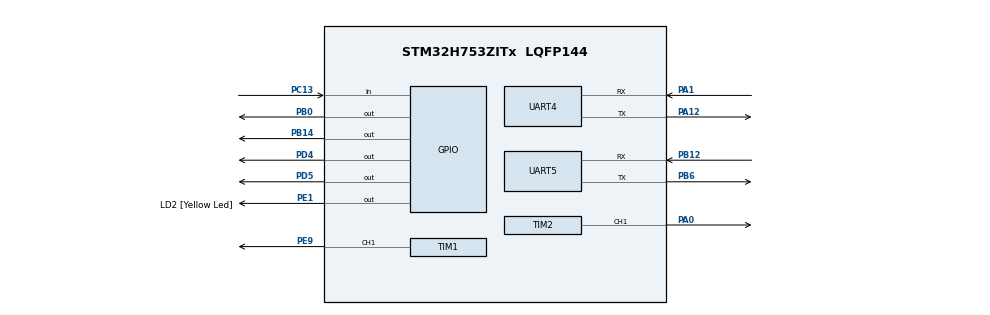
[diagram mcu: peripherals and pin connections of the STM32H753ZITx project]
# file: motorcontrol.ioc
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CORTEX_M7.CPU_DCache=Disabled
CORTEX_M7.CPU_ICache=Disabled
CORTEX_M7.MPU_Control=__NULL
CORTEX_M7.default_mode_Activation=1
Mcu.Family=STM32H7
Mcu.Name=STM32H753ZITx
Mcu.Package=LQFP144
NUCLEO-H753ZI.BUTTON=1
NUCLEO-H753ZI.LD1=true
NUCLEO-H753ZI.LD2=true
NUCLEO-H753ZI.LD3=true
NUCLEO-H753ZI.VCP=true
NVIC.EXTI15_10_IRQn=true\:0\:0\:false\:false\:true\:false\:true\:true
NVIC.PriorityGroup=NVIC_PRIORITYGROUP_4
PA0.Signal=S_TIM2_CH1_ETR
PA1.Mode=Asynchronous
PA1.Signal=UART4_RX
PA12.Mode=Asynchronous
PA12.Signal=UART4_TX
PB0.Signal=GPIO_Output
PB12.Mode=Asynchronous
PB12.Signal=UART5_RX
PB14.Signal=GPIO_Output
PB6.Mode=Asynchronous
PB6.Signal=UART5_TX
PC13.Signal=GPIO_Input
PC14-OSC32_IN\ (OSC32_IN).Signal=RCC_OSC32_IN
PC15-OSC32_OUT\ (OSC32_OUT).Signal=RCC_OSC32_OUT
PD4.Signal=GPIO_Output
PD5.Signal=GPIO_Output
PD8.Signal=USART3_TX
PD9.Signal=USART3_RX
PE1.GPIO_Label=LD2 [Yellow Led]
PE1.Signal=GPIO_Output
PE9.Signal=S_TIM1_CH1
PH0-OSC_IN\ (PH0).Signal=RCC_OSC_IN
PH1-OSC_OUT\ (PH1).Signal=RCC_OSC_OUT
ProjectManager.HeapSize=0x200
ProjectManager.StackSize=0x400
ProjectManager.TargetToolchain=STM32CubeIDE
RCC.ADCFreq_Value=129000000
RCC.APB1Freq_Value=64000000
RCC.APB2Freq_Value=64000000
RCC.APB3Freq_Value=64000000
RCC.APB4Freq_Value=64000000
RCC.CortexFreq_Value=64000000
RCC.DIVM1=1
RCC.DIVN1=24
RCC.DIVQ1=4
RCC.HCLKFreq_Value=64000000
RCC.HSE_VALUE=8000000
RCC.PLLFRACN=0
RCC.PWR_Regulator_Voltage_Scale=PWR_REGULATOR_VOLTAGE_SCALE2
RCC.SYSCLKFreq_VALUE=64000000
RCC.USBFreq_Value=384000000
SH.S_TIM1_CH1.0=TIM1_CH1,PWM Generation1 CH1
SH.S_TIM2_CH1_ETR.0=TIM2_CH1,PWM Generation1 CH1
TIM1.Channel-PWM\ Generation1\ CH1=TIM_CHANNEL_1
TIM1.Period=999
TIM1.Prescaler=239
TIM2.Channel-PWM\ Generation1\ CH1=TIM_CHANNEL_1
VP_MEMORYMAP_VS_MEMORYMAP.Mode=CurAppReg
VP_NUCLEO-H753ZI_VS_BSP_COMMON.Mode=COMMON
board=NUCLEO-H753ZI

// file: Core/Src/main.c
/* USER CODE BEGIN Header */
	/**
	  ******************************************************************************
	  * @file           : main.c
	  * @brief          : Main program body
	  ******************************************************************************
	  * @attention
	  *
	  * Copyright (c) 2025 STMicroelectronics.
	  * All rights reserved.
	  *
	  * This software is licensed under terms that can be found in the LICENSE file
	  * in the root directory of this software component.
	  * If no LICENSE file comes with this software, it is provided AS-IS.
	  *
	  ******************************************************************************
	  */
/* USER CODE END Header */
#include "main.h"

COM_InitTypeDef BspCOMInit;

TIM_HandleTypeDef htim1;
TIM_HandleTypeDef htim2;

UART_HandleTypeDef huart4;
UART_HandleTypeDef huart5;

void SystemClock_Config(void);
static void MX_GPIO_Init(void);
static void MX_TIM1_Init(void);
static void MX_TIM2_Init(void);
static void MX_UART4_Init(void);
static void MX_UART5_Init(void);

int main(void)
{

  /* MCU Configuration--------------------------------------------------------*/

  /* Reset of all peripherals, Initializes the Flash interface and the Systick. */
  HAL_Init();

  /* Configure the system clock */
  SystemClock_Config();

  /* Initialize all configured peripherals */
  MX_GPIO_Init();
  MX_TIM1_Init();
  MX_TIM2_Init();
  MX_UART4_Init();
  MX_UART5_Init();

  /* Initialize leds */
  BSP_LED_Init(LED_GREEN);
  BSP_LED_Init(LED_BLUE);
  BSP_LED_Init(LED_RED);

  /* Initialize USER push-button, will be used to trigger an interrupt each time it's pressed.*/
  BSP_PB_Init(BUTTON_USER, BUTTON_MODE_EXTI);

  /* Initialize COM1 port (115200, 8 bits (7-bit data + 1 stop bit), no parity */
  BspCOMInit.BaudRate   = 115200;
  BspCOMInit.WordLength = COM_WORDLENGTH_8B;
  BspCOMInit.StopBits   = COM_STOPBITS_1;
  BspCOMInit.Parity     = COM_PARITY_NONE;
  BspCOMInit.HwFlowCtl  = COM_HWCONTROL_NONE;
  if (BSP_COM_Init(COM1, &BspCOMInit) != BSP_ERROR_NONE)
  {
    Error_Handler();
  }

  /* Infinite loop */
  while (1)
  {

  }
}

void SystemClock_Config(void)
{
  RCC_OscInitTypeDef RCC_OscInitStruct = {0};
  RCC_ClkInitTypeDef RCC_ClkInitStruct = {0};

  /** Supply configuration update enable
  */
  HAL_PWREx_ConfigSupply(PWR_LDO_SUPPLY);

  /** Configure the main internal regulator output voltage
  */
  __HAL_PWR_VOLTAGESCALING_CONFIG(PWR_REGULATOR_VOLTAGE_SCALE2);

  while(!__HAL_PWR_GET_FLAG(PWR_FLAG_VOSRDY)) {}

  /** Initializes the RCC Oscillators according to the specified parameters
  * in the RCC_OscInitTypeDef structure.
  */
  RCC_OscInitStruct.OscillatorType = RCC_OSCILLATORTYPE_HSI;
  RCC_OscInitStruct.HSIState = RCC_HSI_DIV1;
  RCC_OscInitStruct.HSICalibrationValue = RCC_HSICALIBRATION_DEFAULT;
  RCC_OscInitStruct.PLL.PLLState = RCC_PLL_NONE;
  if (HAL_RCC_OscConfig(&RCC_OscInitStruct) != HAL_OK)
  {
    Error_Handler();
  }

  /** Initializes the CPU, AHB and APB buses clocks
  */
  RCC_ClkInitStruct.ClockType = RCC_CLOCKTYPE_HCLK|RCC_CLOCKTYPE_SYSCLK
                              |RCC_CLOCKTYPE_PCLK1|RCC_CLOCKTYPE_PCLK2
                              |RCC_CLOCKTYPE_D3PCLK1|RCC_CLOCKTYPE_D1PCLK1;
  RCC_ClkInitStruct.SYSCLKSource = RCC_SYSCLKSOURCE_HSI;
  RCC_ClkInitStruct.SYSCLKDivider = RCC_SYSCLK_DIV1;
  RCC_ClkInitStruct.AHBCLKDivider = RCC_HCLK_DIV1;
  RCC_ClkInitStruct.APB3CLKDivider = RCC_APB3_DIV1;
  RCC_ClkInitStruct.APB1CLKDivider = RCC_APB1_DIV1;
  RCC_ClkInitStruct.APB2CLKDivider = RCC_APB2_DIV1;
  RCC_ClkInitStruct.APB4CLKDivider = RCC_APB4_DIV1;

  if (HAL_RCC_ClockConfig(&RCC_ClkInitStruct, FLASH_LATENCY_1) != HAL_OK)
  {
    Error_Handler();
  }
}

static void MX_TIM1_Init(void)
{

  TIM_MasterConfigTypeDef sMasterConfig = {0};
  TIM_OC_InitTypeDef sConfigOC = {0};
  TIM_BreakDeadTimeConfigTypeDef sBreakDeadTimeConfig = {0};

  htim1.Instance = TIM1;
  htim1.Init.Prescaler = 239;
  htim1.Init.CounterMode = TIM_COUNTERMODE_UP;
  htim1.Init.Period = 999;
  htim1.Init.ClockDivision = TIM_CLOCKDIVISION_DIV1;
  htim1.Init.RepetitionCounter = 0;
  htim1.Init.AutoReloadPreload = TIM_AUTORELOAD_PRELOAD_DISABLE;
  if (HAL_TIM_PWM_Init(&htim1) != HAL_OK)
  {
    Error_Handler();
  }
  sMasterConfig.MasterOutputTrigger = TIM_TRGO_RESET;
  sMasterConfig.MasterOutputTrigger2 = TIM_TRGO2_RESET;
  sMasterConfig.MasterSlaveMode = TIM_MASTERSLAVEMODE_DISABLE;
  if (HAL_TIMEx_MasterConfigSynchronization(&htim1, &sMasterConfig) != HAL_OK)
  {
    Error_Handler();
  }
  sConfigOC.OCMode = TIM_OCMODE_PWM1;
  sConfigOC.Pulse = 0;
  sConfigOC.OCPolarity = TIM_OCPOLARITY_HIGH;
  sConfigOC.OCNPolarity = TIM_OCNPOLARITY_HIGH;
  sConfigOC.OCFastMode = TIM_OCFAST_DISABLE;
  sConfigOC.OCIdleState = TIM_OCIDLESTATE_RESET;
  sConfigOC.OCNIdleState = TIM_OCNIDLESTATE_RESET;
  if (HAL_TIM_PWM_ConfigChannel(&htim1, &sConfigOC, TIM_CHANNEL_1) != HAL_OK)
  {
    Error_Handler();
  }
  sBreakDeadTimeConfig.OffStateRunMode = TIM_OSSR_DISABLE;
  sBreakDeadTimeConfig.OffStateIDLEMode = TIM_OSSI_DISABLE;
  sBreakDeadTimeConfig.LockLevel = TIM_LOCKLEVEL_OFF;
  sBreakDeadTimeConfig.DeadTime = 0;
  sBreakDeadTimeConfig.BreakState = TIM_BREAK_DISABLE;
  sBreakDeadTimeConfig.BreakPolarity = TIM_BREAKPOLARITY_HIGH;
  sBreakDeadTimeConfig.BreakFilter = 0;
  sBreakDeadTimeConfig.Break2State = TIM_BREAK2_DISABLE;
  sBreakDeadTimeConfig.Break2Polarity = TIM_BREAK2POLARITY_HIGH;
  sBreakDeadTimeConfig.Break2Filter = 0;
  sBreakDeadTimeConfig.AutomaticOutput = TIM_AUTOMATICOUTPUT_DISABLE;
  if (HAL_TIMEx_ConfigBreakDeadTime(&htim1, &sBreakDeadTimeConfig) != HAL_OK)
  {
    Error_Handler();
  }
  HAL_TIM_MspPostInit(&htim1);

}

static void MX_TIM2_Init(void)
{

  TIM_MasterConfigTypeDef sMasterConfig = {0};
  TIM_OC_InitTypeDef sConfigOC = {0};

  htim2.Instance = TIM2;
  htim2.Init.Prescaler = 0;
  htim2.Init.CounterMode = TIM_COUNTERMODE_UP;
  htim2.Init.Period = 4294967295;
  htim2.Init.ClockDivision = TIM_CLOCKDIVISION_DIV1;
  htim2.Init.AutoReloadPreload = TIM_AUTORELOAD_PRELOAD_DISABLE;
  if (HAL_TIM_PWM_Init(&htim2) != HAL_OK)
  {
    Error_Handler();
  }
  sMasterConfig.MasterOutputTrigger = TIM_TRGO_RESET;
  sMasterConfig.MasterSlaveMode = TIM_MASTERSLAVEMODE_DISABLE;
  if (HAL_TIMEx_MasterConfigSynchronization(&htim2, &sMasterConfig) != HAL_OK)
  {
    Error_Handler();
  }
  sConfigOC.OCMode = TIM_OCMODE_PWM1;
  sConfigOC.Pulse = 0;
  sConfigOC.OCPolarity = TIM_OCPOLARITY_HIGH;
  sConfigOC.OCFastMode = TIM_OCFAST_DISABLE;
  if (HAL_TIM_PWM_ConfigChannel(&htim2, &sConfigOC, TIM_CHANNEL_1) != HAL_OK)
  {
    Error_Handler();
  }
  HAL_TIM_MspPostInit(&htim2);

}

static void MX_UART4_Init(void)
{

  huart4.Instance = UART4;
  huart4.Init.BaudRate = 115200;
  huart4.Init.WordLength = UART_WORDLENGTH_8B;
  huart4.Init.StopBits = UART_STOPBITS_1;
  huart4.Init.Parity = UART_PARITY_NONE;
  huart4.Init.Mode = UART_MODE_TX_RX;
  huart4.Init.HwFlowCtl = UART_HWCONTROL_NONE;
  huart4.Init.OverSampling = UART_OVERSAMPLING_16;
  huart4.Init.OneBitSampling = UART_ONE_BIT_SAMPLE_DISABLE;
  huart4.Init.ClockPrescaler = UART_PRESCALER_DIV1;
  huart4.AdvancedInit.AdvFeatureInit = UART_ADVFEATURE_NO_INIT;
  if (HAL_UART_Init(&huart4) != HAL_OK)
  {
    Error_Handler();
  }
  if (HAL_UARTEx_SetTxFifoThreshold(&huart4, UART_TXFIFO_THRESHOLD_1_8) != HAL_OK)
  {
    Error_Handler();
  }
  if (HAL_UARTEx_SetRxFifoThreshold(&huart4, UART_RXFIFO_THRESHOLD_1_8) != HAL_OK)
  {
    Error_Handler();
  }
  if (HAL_UARTEx_DisableFifoMode(&huart4) != HAL_OK)
  {
    Error_Handler();
  }

}

static void MX_UART5_Init(void)
{

  huart5.Instance = UART5;
  huart5.Init.BaudRate = 115200;
  huart5.Init.WordLength = UART_WORDLENGTH_8B;
  huart5.Init.StopBits = UART_STOPBITS_1;
  huart5.Init.Parity = UART_PARITY_NONE;
  huart5.Init.Mode = UART_MODE_TX_RX;
  huart5.Init.HwFlowCtl = UART_HWCONTROL_NONE;
  huart5.Init.OverSampling = UART_OVERSAMPLING_16;
  huart5.Init.OneBitSampling = UART_ONE_BIT_SAMPLE_DISABLE;
  huart5.Init.ClockPrescaler = UART_PRESCALER_DIV1;
  huart5.AdvancedInit.AdvFeatureInit = UART_ADVFEATURE_NO_INIT;
  if (HAL_UART_Init(&huart5) != HAL_OK)
  {
    Error_Handler();
  }
  if (HAL_UARTEx_SetTxFifoThreshold(&huart5, UART_TXFIFO_THRESHOLD_1_8) != HAL_OK)
  {
    Error_Handler();
  }
  if (HAL_UARTEx_SetRxFifoThreshold(&huart5, UART_RXFIFO_THRESHOLD_1_8) != HAL_OK)
  {
    Error_Handler();
  }
  if (HAL_UARTEx_DisableFifoMode(&huart5) != HAL_OK)
  {
    Error_Handler();
  }

}

static void MX_GPIO_Init(void)
{
  GPIO_InitTypeDef GPIO_InitStruct = {0};

  /* GPIO Ports Clock Enable */
  __HAL_RCC_GPIOC_CLK_ENABLE();
  __HAL_RCC_GPIOH_CLK_ENABLE();
  __HAL_RCC_GPIOA_CLK_ENABLE();
  __HAL_RCC_GPIOE_CLK_ENABLE();
  __HAL_RCC_GPIOB_CLK_ENABLE();
  __HAL_RCC_GPIOD_CLK_ENABLE();

  /*Configure GPIO pin Output Level */
  HAL_GPIO_WritePin(GPIOD, GPIO_PIN_4|GPIO_PIN_5, GPIO_PIN_RESET);

  /*Configure GPIO pin Output Level */
  HAL_GPIO_WritePin(LD2_GPIO_Port, LD2_Pin, GPIO_PIN_RESET);

  /*Configure GPIO pins : PD4 PD5 */
  GPIO_InitStruct.Pin = GPIO_PIN_4|GPIO_PIN_5;
  GPIO_InitStruct.Mode = GPIO_MODE_OUTPUT_PP;
  GPIO_InitStruct.Pull = GPIO_NOPULL;
  GPIO_InitStruct.Speed = GPIO_SPEED_FREQ_LOW;
  HAL_GPIO_Init(GPIOD, &GPIO_InitStruct);

  /*Configure GPIO pin : LD2_Pin */
  GPIO_InitStruct.Pin = LD2_Pin;
  GPIO_InitStruct.Mode = GPIO_MODE_OUTPUT_PP;
  GPIO_InitStruct.Pull = GPIO_NOPULL;
  GPIO_InitStruct.Speed = GPIO_SPEED_FREQ_LOW;
  HAL_GPIO_Init(LD2_GPIO_Port, &GPIO_InitStruct);

}

/* USER CODE BEGIN 4 */
	void stop_motor()
	{
		HAL_GPIO_WritePin(GPIOD, GPIO_PIN_4, GPIO_PIN_RESET); // IN1 = Low
		HAL_GPIO_WritePin(GPIOD, GPIO_PIN_5, GPIO_PIN_RESET); // IN2 = Low
		__HAL_TIM_SET_COMPARE(&htim1, TIM_CHANNEL_1, 0); // Stop PWM
	}

	void start_motor()
	{
		HAL_GPIO_WritePin(GPIOD, GPIO_PIN_4, GPIO_PIN_SET);   // IN1 = High
		HAL_GPIO_WritePin(GPIOD, GPIO_PIN_5, GPIO_PIN_RESET); // IN2 = Low
		__HAL_TIM_SET_COMPARE(&htim1, TIM_CHANNEL_1, 500);  // 50% Speed
	}

/* USER CODE END 4 */

void Error_Handler(void)
{
	  __disable_irq();
	  while (1)
	  {
	  }
}
